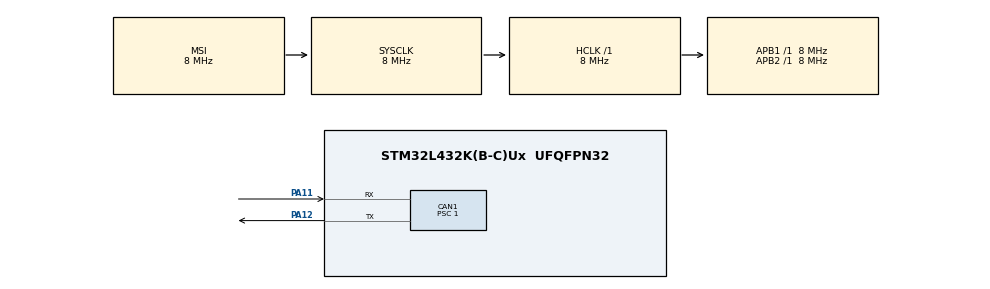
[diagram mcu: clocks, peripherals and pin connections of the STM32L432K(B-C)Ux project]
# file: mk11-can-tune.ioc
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CAN1.BS1=CAN_BS1_13TQ
CAN1.BS2=CAN_BS2_2TQ
CAN1.CalculateBaudRate=500000
CAN1.CalculateTimeBit=2000
CAN1.CalculateTimeQuantum=125.0
CAN1.Mode=CAN_MODE_NORMAL
CAN1.Prescaler=1
Mcu.Family=STM32L4
Mcu.Name=STM32L432K(B-C)Ux
Mcu.Package=UFQFPN32
NVIC.CAN1_RX0_IRQn=true\:0\:0\:false\:false\:true\:true\:true\:true
NVIC.PriorityGroup=NVIC_PRIORITYGROUP_4
PA11.GPIO_PuPd=GPIO_PULLUP
PA11.Mode=CAN_Activate
PA11.Signal=CAN1_RX
PA12.Mode=CAN_Activate
PA12.Signal=CAN1_TX
ProjectManager.HeapSize=0x200
ProjectManager.StackSize=0x400
ProjectManager.TargetToolchain=STM32CubeIDE
RCC.ADCFreq_Value=32000000
RCC.AHBFreq_Value=8000000
RCC.APB1Freq_Value=8000000
RCC.APB1TimFreq_Value=8000000
RCC.APB2Freq_Value=8000000
RCC.APB2TimFreq_Value=8000000
RCC.CortexFreq_Value=8000000
RCC.HCLKFreq_Value=8000000
RCC.HSE_VALUE=8000000
RCC.HSI48_VALUE=48000000
RCC.HSI_VALUE=16000000
RCC.LSE_VALUE=32768
RCC.MSIClockRange=RCC_MSIRANGE_7
RCC.MSI_VALUE=8000000
RCC.SYSCLKFreq_VALUE=8000000
RCC.USBFreq_Value=32000000
RCC.VCOOutputFreq_Value=64000000
board=custom

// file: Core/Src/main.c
/* USER CODE BEGIN Header */
/**
  ******************************************************************************
  * @file           : main.c
  * @brief          : Main program body
  ******************************************************************************
  * @attention
  *
  * Copyright (c) 2025 STMicroelectronics.
  * All rights reserved.
  *
  * This software is licensed under terms that can be found in the LICENSE file
  * in the root directory of this software component.
  * If no LICENSE file comes with this software, it is provided AS-IS.
  *
  ******************************************************************************
  */
/* USER CODE END Header */
#include "main.h"
#include "can.h"
#include "gpio.h"

/* USER CODE BEGIN Includes */
#include "tuning.h"
/* USER CODE END Includes */

/* USER CODE BEGIN PV */
CAN_CONTEXT can_context;
TUNABLE_PARAMETERS params;
int debug = 0;
/* USER CODE END PV */

void SystemClock_Config(void);

/* USER CODE BEGIN 0 */
void HAL_CAN_RxFifo0MsgPendingCallback(CAN_HandleTypeDef *hcan) {
	debug++;
	if (HAL_CAN_GetRxMessage(hcan, CAN_RX_FIFO0, &(can_context.RxHeader), can_context.RxData) != HAL_OK) {
		return;
	}

	if (can_context.RxHeader.StdId == PARAMETER_TUNE_ID &&
		can_context.RxData[0] == MICROCONTROLLER_ID) {
		// Asserts correct StdID + Microcontroller ID
		parameterTuneRxHandler(&can_context, &params);
	} else {
		// TODO
	}
}
/* USER CODE END 0 */

int main(void)
{

  /* MCU Configuration--------------------------------------------------------*/

  /* Reset of all peripherals, Initializes the Flash interface and the Systick. */
  HAL_Init();

  /* Configure the system clock */
  SystemClock_Config();

  /* Initialize all configured peripherals */
  MX_GPIO_Init();
  MX_CAN1_Init();
  /* USER CODE BEGIN 2 */
  CAN_FilterTypeDef sFilterConfig;

  sFilterConfig.FilterBank = 0;
  sFilterConfig.FilterMode = CAN_FILTERMODE_IDMASK;
  sFilterConfig.FilterScale = CAN_FILTERSCALE_32BIT;
  sFilterConfig.FilterIdHigh = 0x0000;
  sFilterConfig.FilterIdLow = 0x0000;
  sFilterConfig.FilterMaskIdHigh = 0x0000;
  sFilterConfig.FilterMaskIdLow = 0x0000;
  sFilterConfig.FilterFIFOAssignment = CAN_RX_FIFO0;
  sFilterConfig.FilterActivation = ENABLE;
  sFilterConfig.SlaveStartFilterBank = 14;

  HAL_CAN_ConfigFilter(&hcan1, &sFilterConfig);

  HAL_CAN_Start(&hcan1);
  HAL_CAN_ActivateNotification(&hcan1, CAN_IT_RX_FIFO0_MSG_PENDING);

  /* USER CODE END 2 */

  /* Infinite loop */
  while (1)
  {

  }
}

void SystemClock_Config(void)
{
  RCC_OscInitTypeDef RCC_OscInitStruct = {0};
  RCC_ClkInitTypeDef RCC_ClkInitStruct = {0};

  /** Configure the main internal regulator output voltage
  */
  if (HAL_PWREx_ControlVoltageScaling(PWR_REGULATOR_VOLTAGE_SCALE1) != HAL_OK)
  {
    Error_Handler();
  }

  /** Initializes the RCC Oscillators according to the specified parameters
  * in the RCC_OscInitTypeDef structure.
  */
  RCC_OscInitStruct.OscillatorType = RCC_OSCILLATORTYPE_MSI;
  RCC_OscInitStruct.MSIState = RCC_MSI_ON;
  RCC_OscInitStruct.MSICalibrationValue = 0;
  RCC_OscInitStruct.MSIClockRange = RCC_MSIRANGE_7;
  RCC_OscInitStruct.PLL.PLLState = RCC_PLL_NONE;
  if (HAL_RCC_OscConfig(&RCC_OscInitStruct) != HAL_OK)
  {
    Error_Handler();
  }

  /** Initializes the CPU, AHB and APB buses clocks
  */
  RCC_ClkInitStruct.ClockType = RCC_CLOCKTYPE_HCLK|RCC_CLOCKTYPE_SYSCLK
                              |RCC_CLOCKTYPE_PCLK1|RCC_CLOCKTYPE_PCLK2;
  RCC_ClkInitStruct.SYSCLKSource = RCC_SYSCLKSOURCE_MSI;
  RCC_ClkInitStruct.AHBCLKDivider = RCC_SYSCLK_DIV1;
  RCC_ClkInitStruct.APB1CLKDivider = RCC_HCLK_DIV1;
  RCC_ClkInitStruct.APB2CLKDivider = RCC_HCLK_DIV1;

  if (HAL_RCC_ClockConfig(&RCC_ClkInitStruct, FLASH_LATENCY_0) != HAL_OK)
  {
    Error_Handler();
  }
}

void Error_Handler(void)
{
  __disable_irq();
  while (1)
  {
  }
}
